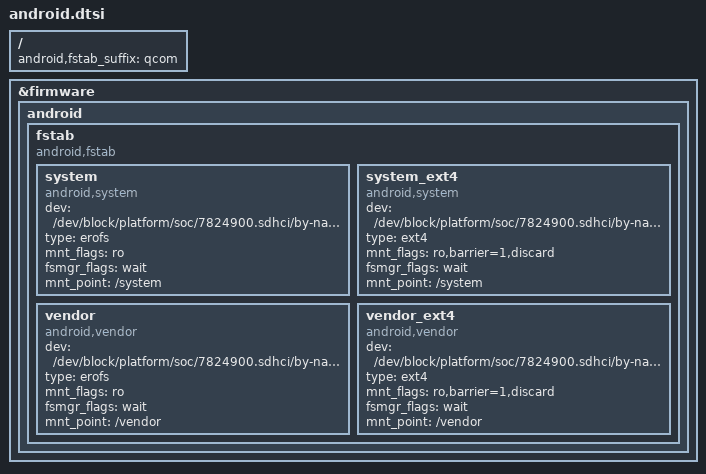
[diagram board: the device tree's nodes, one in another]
/ {
	android,fstab_suffix = "qcom";
};

&firmware {
	android {
		/delete-node/ vbmeta;
		/delete-node/ fstab;

		fstab {
			compatible = "android,fstab";

			system {
				compatible = "android,system";
				dev = "/dev/block/platform/soc/7824900.sdhci/by-name/system";
				type = "erofs";
				mnt_flags = "ro";
				fsmgr_flags = "wait";
				mnt_point = "/system";
				status = "ok";
			};

			system_ext4 {
				compatible = "android,system";
				dev = "/dev/block/platform/soc/7824900.sdhci/by-name/system";
				type = "ext4";
				mnt_flags = "ro,barrier=1,discard";
				fsmgr_flags = "wait";
				mnt_point = "/system";
				status = "ok";
			};

			vendor {
				compatible = "android,vendor";
				dev = "/dev/block/platform/soc/7824900.sdhci/by-name/cust";
				type = "erofs";
				mnt_flags = "ro";
				fsmgr_flags = "wait";
				mnt_point = "/vendor";
				status = "ok";
			};

			vendor_ext4 {
				compatible = "android,vendor";
				dev = "/dev/block/platform/soc/7824900.sdhci/by-name/cust";
				type = "ext4";
				mnt_flags = "ro,barrier=1,discard";
				fsmgr_flags = "wait";
				mnt_point = "/vendor";
				status = "ok";
			};
		};
	};
};
